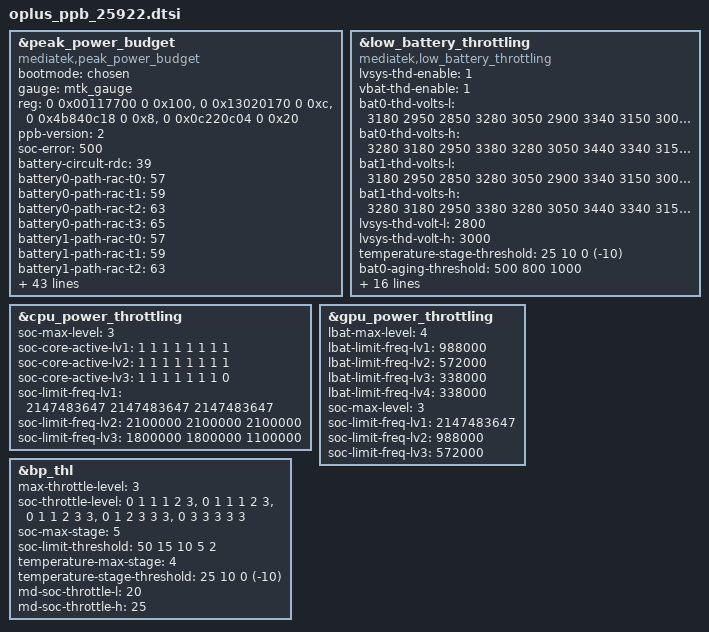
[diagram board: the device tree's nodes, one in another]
// SPDX-License-Identifier: GPL-2.0-only
/*
* Copyright (C) 2021-2020 Oplus. All rights reserved.
*/
#include <dt-bindings/iio/mt635x-auxadc.h>
#include <dt-bindings/pinctrl/mt6991-pinfunc.h>
#include <dt-bindings/pinctrl/mt65xx.h>

&peak_power_budget {
	compatible = "mediatek,peak_power_budget";
	bootmode = <&chosen>;
	gauge = <&mtk_gauge>;
	reg = <0 0x00117700 0 0x100>,
		<0 0x13020170 0 0xc>,
		<0 0x4b840c18 0 0x8>,
		<0 0x0c220c04 0 0x20>;
	reg-names = "ppb_sram",
		"hpt_ctrl","gpu_dbg", "cpu_dbg";

	ppb-version = <2>;
	soc-error = <500>;
	battery-circult-rdc  = <39>;
	battery0-path-rac-t0 = <57>;
	battery0-path-rac-t1 = <59>;
	battery0-path-rac-t2 = <63>;
	battery0-path-rac-t3 = <65>;
	battery1-path-rac-t0 = <57>;
	battery1-path-rac-t1 = <59>;
	battery1-path-rac-t2 = <63>;
	battery1-path-rac-t3 = <65>;
	battery2-path-rac-t0 = <57>;
	battery2-path-rac-t1 = <59>;
	battery2-path-rac-t2 = <63>;
	battery2-path-rac-t3 = <65>;
	temperature-threshold = <25 10 0>;
	system-ocp = <15000>;
	system-uvlo = <2400>;

	soc-max-level = <3>;     //+lv3
	soc-hpt-ctrl-lv1 = <7>;  //lv1 pre-uv on
	soc-hpt-ctrl-lv2 = <7>;  //lv2 pre-uv on  //modify for tablet projects configured graphite battery 
	soc-hpt-ctrl-lv3 = <0>;  //lv3 pre-uv off

	bat-ocv-table-num = <6>;
	bat0-ocv-table-t0-temperature = <50>;
		bat0-ocv-table-t0-qmax = <5443>;
	bat0-ocv-table-t0-size = <100>;
	bat0-ocv-table-t0 = <
			0		44549	0 		342
			550		44408	101 	341
			1100	44302	202 	353
			1649	44213	303 	358
			2199	44122	404 	357
			2749	44031	505 	342
			3299	43945	606 	358
			3848	43852	707 	363
			4398	43757	808 	357
			4948	43662	909 	371
			5498	43560	1010 	361
			6047	43461	1111 	369
			6597	43357	1212 	364
			7147	43253	1313 	372
			7697	43147	1414 	369
			8246	43035	1515 	365
			8796	42927	1616 	388
			9346	42804	1717 	372
			9896	42688	1818 	371
			10445	42575	1919 	387
			10995	42456	2020 	394
			11545	42336	2121 	390
			12095	42218	2222 	405
			12644	42098	2323 	411
			13194	41979	2424 	431
			13744	41857	2525 	432
			14294	41739	2626 	456
			14843	41609	2727 	467
			15393	41467	2828 	491
			15943	41259	2929 	429
			16493	41058	3030 	396
			17042	40908	3131 	371
			17592	40777	3232 	371
			18142	40664	3333 	373
			18692	40553	3434 	370
			19241	40445	3535 	371
			19791	40339	3636 	357
			20341	40239	3737 	370
			20891	40139	3838 	372
			21440	40042	3939 	373
			21990	39945	4040 	371
			22540	39848	4141 	362
			23090	39759	4242 	383
			23639	39672	4343 	387
			24189	39584	4444 	395
			24739	39495	4545 	404
			25289	39403	4646 	406
			25838	39300	4747 	410
			26388	39150	4848 	374
			26938	39000	4949 	362
			27488	38872	5051 	373
			28037	38759	5151 	371
			28587	38645	5252 	379
			29137	38538	5354 	387
			29687	38434	5455 	376
			30236	38332	5555 	388
			30786	38219	5656 	388
			31336	38093	5758 	405
			31886	37974	5859 	412
			32435	37867	5959 	434
			32985	37744	6061 	441
			33535	37633	6162 	436
			34085	37552	6263 	419
			34635	37482	6364 	419
			35184	37422	6465 	421
			35734	37348	6566 	426
			36284	37267	6667 	426
			36834	37148	6768 	426
			37383	37028	6869 	426
			37933	36916	6970 	426
			38483	36803	7071 	426
			39033	36680	7172 	426
			39582	36553	7273 	426
			40132	36421	7374 	426
			40682	36280	7475 	426
			41232	36138	7576 	426
			41781	35984	7677 	426
			42331	35826	7778 	426
			42881	35664	7879 	426
			43431	35502	7980 	426
			43980	35352	8081 	426
			44530	35199	8182 	426
			45080	35046	8283 	426
			45630	34899	8384 	426
			46179	34745	8485 	426
			46729	34582	8586 	426
			47279	34411	8687 	426
			47829	34238	8788 	426
			48378	34048	8889 	426
			48928	33830	8990 	426
			49478	33610	9091 	426
			50028	33380	9192 	426
			50577	33144	9293 	426
			51127	32918	9394 	426
			51677	32691	9495 	426
			52227	32473	9596 	426
			52776	32254	9697 	426
			53326	32015	9798 	426
			53876	31732	9899 	426
			54426	31374	10000 	426
		>;         //modify for tablet projects configured graphite battery 

		bat0-ocv-table-t1-temperature = <25>;
		bat0-ocv-table-t1-qmax = <5443>;
		bat0-ocv-table-t1-size = <100>;
		bat0-ocv-table-t1 = <
			0		44549	0 		342
			550		44408	101 	341
			1100	44302	202 	353
			1649	44213	303 	358
			2199	44122	404 	357
			2749	44031	505 	342
			3299	43945	606 	358
			3848	43852	707 	363
			4398	43757	808 	357
			4948	43662	909 	371
			5498	43560	1010 	361
			6047	43461	1111 	369
			6597	43357	1212 	364
			7147	43253	1313 	372
			7697	43147	1414 	369
			8246	43035	1515 	365
			8796	42927	1616 	388
			9346	42804	1717 	372
			9896	42688	1818 	371
			10445	42575	1919 	387
			10995	42456	2020 	394
			11545	42336	2121 	390
			12095	42218	2222 	405
			12644	42098	2323 	411
			13194	41979	2424 	431
			13744	41857	2525 	432
			14294	41739	2626 	456
			14843	41609	2727 	467
			15393	41467	2828 	491
			15943	41259	2929 	429
			16493	41058	3030 	396
			17042	40908	3131 	371
			17592	40777	3232 	371
			18142	40664	3333 	373
			18692	40553	3434 	370
			19241	40445	3535 	371
			19791	40339	3636 	357
			20341	40239	3737 	370
			20891	40139	3838 	372
			21440	40042	3939 	373
			21990	39945	4040 	371
			22540	39848	4141 	362
			23090	39759	4242 	383
			23639	39672	4343 	387
			24189	39584	4444 	395
			24739	39495	4545 	404
			25289	39403	4646 	406
			25838	39300	4747 	410
			26388	39150	4848 	374
			26938	39000	4949 	362
			27488	38872	5051 	373
			28037	38759	5151 	371
			28587	38645	5252 	379
			29137	38538	5354 	387
			29687	38434	5455 	376
			30236	38332	5555 	388
			30786	38219	5656 	388
			31336	38093	5758 	405
			31886	37974	5859 	412
			32435	37867	5959 	434
			32985	37744	6061 	441
			33535	37633	6162 	436
			34085	37552	6263 	419
			34635	37482	6364 	419
			35184	37422	6465 	421
			35734	37348	6566 	426
			36284	37267	6667 	426
			36834	37148	6768 	426
			37383	37028	6869 	426
			37933	36916	6970 	426
			38483	36803	7071 	426
			39033	36680	7172 	426
			39582	36553	7273 	426
			40132	36421	7374 	426
			40682	36280	7475 	426
			41232	36138	7576 	426
			41781	35984	7677 	426
			42331	35826	7778 	426
			42881	35664	7879 	426
			43431	35502	7980 	426
			43980	35352	8081 	426
			44530	35199	8182 	426
			45080	35046	8283 	426
			45630	34899	8384 	426
			46179	34745	8485 	426
			46729	34582	8586 	426
			47279	34411	8687 	426
			47829	34238	8788 	426
			48378	34048	8889 	426
			48928	33830	8990 	426
			49478	33610	9091 	426
			50028	33380	9192 	426
			50577	33144	9293 	426
			51127	32918	9394 	426
			51677	32691	9495 	426
			52227	32473	9596 	426
			52776	32254	9697 	426
			53326	32015	9798 	426
			53876	31732	9899 	426
			54426	31374	10000 	426
		>;         //modify for tablet projects configured graphite battery 
		
		
		bat0-ocv-table-t2-temperature = <10>;
		bat0-ocv-table-t2-qmax = <5443>;
		bat0-ocv-table-t2-size = <100>;
		bat0-ocv-table-t2 = <
			0		44549	0 		342
			550		44408	101 	341
			1100	44302	202 	353
			1649	44213	303 	358
			2199	44122	404 	357
			2749	44031	505 	342
			3299	43945	606 	358
			3848	43852	707 	363
			4398	43757	808 	357
			4948	43662	909 	371
			5498	43560	1010 	361
			6047	43461	1111 	369
			6597	43357	1212 	364
			7147	43253	1313 	372
			7697	43147	1414 	369
			8246	43035	1515 	365
			8796	42927	1616 	388
			9346	42804	1717 	372
			9896	42688	1818 	371
			10445	42575	1919 	387
			10995	42456	2020 	394
			11545	42336	2121 	390
			12095	42218	2222 	405
			12644	42098	2323 	411
			13194	41979	2424 	431
			13744	41857	2525 	432
			14294	41739	2626 	456
			14843	41609	2727 	467
			15393	41467	2828 	491
			15943	41259	2929 	429
			16493	41058	3030 	396
			17042	40908	3131 	371
			17592	40777	3232 	371
			18142	40664	3333 	373
			18692	40553	3434 	370
			19241	40445	3535 	371
			19791	40339	3636 	357
			20341	40239	3737 	370
			20891	40139	3838 	372
			21440	40042	3939 	373
			21990	39945	4040 	371
			22540	39848	4141 	362
			23090	39759	4242 	383
			23639	39672	4343 	387
			24189	39584	4444 	395
			24739	39495	4545 	404
			25289	39403	4646 	406
			25838	39300	4747 	410
			26388	39150	4848 	374
			26938	39000	4949 	362
			27488	38872	5051 	373
			28037	38759	5151 	371
			28587	38645	5252 	379
			29137	38538	5354 	387
			29687	38434	5455 	376
			30236	38332	5555 	388
			30786	38219	5656 	388
			31336	38093	5758 	405
			31886	37974	5859 	412
			32435	37867	5959 	434
			32985	37744	6061 	441
			33535	37633	6162 	436
			34085	37552	6263 	419
			34635	37482	6364 	419
			35184	37422	6465 	421
			35734	37348	6566 	426
			36284	37267	6667 	426
			36834	37148	6768 	426
			37383	37028	6869 	426
			37933	36916	6970 	426
			38483	36803	7071 	426
			39033	36680	7172 	426
			39582	36553	7273 	426
			40132	36421	7374 	426
			40682	36280	7475 	426
			41232	36138	7576 	426
			41781	35984	7677 	426
			42331	35826	7778 	426
			42881	35664	7879 	426
			43431	35502	7980 	426
			43980	35352	8081 	426
			44530	35199	8182 	426
			45080	35046	8283 	426
			45630	34899	8384 	426
			46179	34745	8485 	426
			46729	34582	8586 	426
			47279	34411	8687 	426
			47829	34238	8788 	426
			48378	34048	8889 	426
			48928	33830	8990 	426
			49478	33610	9091 	426
			50028	33380	9192 	426
			50577	33144	9293 	426
			51127	32918	9394 	426
			51677	32691	9495 	426
			52227	32473	9596 	426
			52776	32254	9697 	426
			53326	32015	9798 	426
			53876	31732	9899 	426
			54426	31374	10000 	426
		>;         //modify for tablet projects configured graphite battery 
		
		bat0-ocv-table-t3-temperature = <0>;
		bat0-ocv-table-t3-qmax = <5028>;
		bat0-ocv-table-t3-size = <100>;
		bat0-ocv-table-t3 = <
			0		44847	0 		2400
			508		44613	101 	2656
			1016	44464	202 	2649
			1524	44358	303 	2622
			2031	44264	404 	2631
			2539	44177	505 	2606
			3047	44095	606 	2594
			3555	44010	707 	2572
			4063	43930	808 	2558
			4571	43843	909 	2558
			5078	43756	1010 	2544
			5586	43663	1111 	2539
			6094	43574	1212 	2519
			6602	43480	1313 	2525
			7110	43380	1414 	2514
			7618	43289	1515 	2521
			8126	43181	1616 	2501
			8633	43078	1717 	2496
			9141	42970	1818 	2485
			9649	42865	1919 	2496
			10157	42752	2020 	2483
			10665	42641	2121 	2481
			11173	42523	2222 	2482
			11680	42416	2323 	2482
			12188	42301	2424 	2496
			12696	42186	2525 	2493
			13204	42068	2626 	2463
			13712	41953	2727 	2433
			14220	41830	2828 	2403
			14728	41712	2929 	2373
			15235	41586	3030 	2343
			15743	41452	3131 	2313
			16251	41304	3232 	2283
			16759	41146	3333 	2200
			17267	40973	3434 	2120
			17775	40806	3535 	2040
			18282	40658	3636 	1960
			18790	40530	3737 	1880
			19298	40416	3838 	1800
			19806	40309	3939 	1800
			20314	40204	4040 	1800
			20822	40103	4141 	1800
			21330	40008	4242 	1800
			21837	39913	4343 	1800
			22345	39825	4444 	1800
			22853	39733	4545 	1800
			23361	39648	4646 	1800
			23869	39563	4747 	1800
			24377	39484	4849 	1800
			24885	39406	4950 	1800
			25392	39327	5050 	1800
			25900	39248	5151 	1800
			26408	39170	5253 	1800
			26916	39099	5354 	1800
			27424	39023	5455 	1800
			27932	38950	5556 	1800
			28439	38865	5656 	1800
			28947	38780	5758 	1800
			29455	38691	5859 	1800
			29963	38584	5960 	1800
			30471	38485	6061 	1800
			30979	38382	6162 	1800
			31487	38282	6263 	1800
			31994	38171	6364 	1800
			32502	38053	6465 	1800
			33010	37939	6566 	1800
			33518	37822	6667 	1600
			34026	37708	6768 	1600
			34534	37589	6869 	1600
			35041	37503	6970 	1580
			35549	37439	7071 	1560
			36057	37372	7172 	1540
			36565	37317	7273 	1520
			37073	37245	7374 	1500
			37581	37140	7475 	1480
			38089	36969	7576 	1460
			38596	36822	7677 	1440
			39104	36693	7778 	1420
			39612	36573	7879 	1400
			40120	36447	7980 	1400
			40628	36326	8081 	1400
			41136	36187	8182 	1400
			41643	36054	8283 	1400
			42151	35912	8384 	1400
			42659	35756	8485 	1400
			43167	35599	8586 	1400
			43675	35438	8687 	1400
			44183	35277	8788 	1400
			44691	35119	8889 	1350
			45198	34959	8990 	1300
			45706	34797	9091 	1250
			46214	34634	9192 	1200
			46722	34462	9293 	1200
			47230	34286	9394 	1100
			47738	34104	9495 	1100
			48245	33906	9596 	1100
			48753	33693	9697 	1000
			49261	33472	9798 	800
			49769	33239	9899 	800
			50277	33004	10000 	700
		>;

		bat0-ocv-table-t4-temperature = <(-10)>;
		bat0-ocv-table-t4-qmax = <4804>;
		bat0-ocv-table-t4-size = <100>;
		bat0-ocv-table-t4 = <
			0		44847	0 		3500
			485		44601	101 	3500
			970		44452	202 	3500
			1456	44343	303 	3500
			1941	44240	404 	3500
			2426	44142	505 	3500
			2911	44058	606 	3500
			3396	43971	707 	3500
			3882	43888	808 	3500
			4367	43805	909 	3500
			4852	43717	1010 	3500
			5337	43633	1111 	3500
			5822	43548	1212 	3500
			6308	43453	1313 	3500
			6793	43362	1414 	3500
			7278	43265	1515 	3500
			7763	43172	1616 	3500
			8248	43078	1717 	3500
			8734	42978	1818 	3500
			9219	42879	1919 	3500
			9704	42774	2020 	3500
			10189	42671	2121 	3500
			10674	42561	2222 	3500
			11160	42452	2323 	3500
			11645	42341	2424 	3500
			12130	42238	2525 	3500
			12615	42117	2626 	3500
			13100	42006	2727 	3500
			13586	41889	2828 	3500
			14071	41764	2929 	3500
			14556	41647	3030 	3500
			15041	41522	3131 	3500
			15526	41417	3232 	3500
			16012	41269	3333 	3500
			16497	41120	3434 	3500
			16982	40975	3535 	3500
			17467	40833	3636 	3500
			17952	40697	3737 	3500
			18437	40575	3838 	3500
			18923	40452	3939 	3500
			19408	40347	4040 	3500
			19893	40246	4141 	3500
			20378	40143	4242 	3500
			20863	40050	4343 	3500
			21349	39957	4444 	3400
			21834	39868	4545 	3350
			22319	39780	4646 	3300
			22804	39690	4747 	3250
			23289	39613	4848 	3200
			23775	39528	4950 	3150
			24260	39449	5050 	3100
			24745	39376	5151 	3050
			25230	39296	5252 	3000
			25715	39227	5353 	3000
			26201	39152	5455 	3000
			26686	39081	5556 	3000
			27171	39008	5657 	3000
			27656	38939	5757 	3000
			28141	38868	5858 	3000
			28627	38791	5960 	3000
			29112	38715	6061 	3000
			29597	38638	6162 	3000
			30082	38550	6263 	3000
			30567	38465	6363 	3000
			31053	38375	6465 	3000
			31538	38279	6566 	2900
			32023	38182	6667 	2800
			32508	38071	6768 	2700
			32993	37965	6869 	2600
			33479	37856	6970 	2500
			33964	37748	7071 	2500
			34449	37631	7172 	2500
			34934	37529	7273 	2500
			35419	37448	7374 	2500
			35905	37384	7475 	2500
			36390	37324	7576 	2500
			36875	37270	7677 	2500
			37360	37208	7778 	2500
			37845	37117	7879 	2500
			38331	36949	7980 	2500
			38816	36766	8081 	2500
			39301	36637	8182 	2500
			39786	36512	8283 	2500
			40271	36387	8384 	2500
			40757	36270	8485 	2500
			41242	36144	8586 	2500
			41727	36016	8687 	2500
			42212	35883	8788 	2500
			42697	35736	8889 	2500
			43183	35586	8990 	2500
			43668	35423	9091 	2500
			44153	35261	9192 	2500
			44638	35088	9293 	2500
			45123	34920	9394 	2500
			45609	34748	9495 	2500
			46094	34570	9596 	2500
			46579	34395	9697 	2500
			47064	34211	9798 	2500
			47549	34023	9899 	2500
			48035	33829	10000 	2500
		>;

		bat0-ocv-table-t5-temperature = <(-20)>;
		bat0-ocv-table-t5-qmax = <4180>;
		bat0-ocv-table-t5-size = <100>;
		bat0-ocv-table-t5 = <
			0		44624	0 		3450
			422		44416	101 	3450
			844		44269	202 	3450
			1267	44151	303 	3450
			1689	44036	404 	3450
			2111	43930	505 	3450
			2533	43829	606 	3475
			2955	43735	707 	3500
			3377	43642	808 	3525
			3800	43550	909 	3550
			4222	43455	1010 	3575
			4644	43367	1111 	3600
			5066	43277	1212 	3625
			5488	43190	1313 	3650
			5911	43099	1414 	3700
			6333	43012	1515 	3730
			6755	42915	1616 	3760
			7177	42823	1717 	3790
			7599	42731	1818 	3820
			8021	42639	1919 	3850
			8444	42545	2020 	3880
			8866	42447	2121 	3910
			9288	42350	2222 	3940
			9710	42255	2323 	3970
			10132	42157	2424 	4000
			10554	42055	2525 	4100
			10977	41954	2626 	4200
			11399	41855	2727 	4300
			11821	41748	2828 	4400
			12243	41636	2929 	4500
			12665	41529	3030 	4600
			13088	41424	3131 	4700
			13510	41314	3232 	4800
			13932	41195	3333 	5000
			14354	41084	3434 	4900
			14776	40972	3535 	4800
			15198	40862	3636 	4700
			15621	40762	3737 	4600
			16043	40659	3838 	4500
			16465	40559	3939 	4500
			16887	40458	4040 	4500
			17309	40356	4141 	4500
			17732	40261	4243 	4500
			18154	40165	4343 	4500
			18576	40075	4444 	4450
			18998	39985	4545 	4400
			19420	39897	4646 	4350
			19842	39817	4747 	4300
			20265	39739	4849 	4250
			20687	39659	4950 	4200
			21109	39575	5050 	4150
			21531	39503	5151 	4100
			21953	39436	5252 	4050
			22376	39364	5354 	4000
			22798	39292	5455 	3950
			23220	39221	5556 	4000
			23642	39153	5657 	4000
			24064	39084	5757 	4000
			24486	39018	5858 	4000
			24909	38956	5960 	4000
			25331	38889	6061 	4000
			25753	38821	6162 	4000
			26175	38755	6263 	4000
			26597	38689	6364 	4000
			27019	38629	6464 	4000
			27442	38552	6566 	4000
			27864	38485	6667 	4000
			28286	38419	6768 	4000
			28708	38347	6869 	4000
			29130	38275	6970 	4000
			29553	38202	7071 	4000
			29975	38130	7172 	4000
			30397	38055	7273 	4000
			30819	37977	7374 	4000
			31241	37897	7475 	4000
			31663	37818	7576 	4200
			32086	37736	7677 	4400
			32508	37650	7778 	4500
			32930	37574	7879 	4600
			33352	37501	7980 	4850
			33774	37434	8081 	5100
			34197	37374	8182 	5350
			34619	37321	8283 	5600
			35041	37275	8384 	5850
			35463	37227	8485 	6100
			35885	37162	8586 	6350
			36307	37088	8687 	6600
			36730	36974	8788 	6850
			37152	36829	8889 	7100
			37574	36674	8990 	7000
			37996	36529	9091 	7000
			38418	36397	9192 	7000
			38841	36275	9293 	7000
			39263	36157	9394 	7000
			39685	36039	9495 	7000
			40107	35916	9596 	7000
			40529	35785	9697 	7000
			40951	35649	9798 	7400
			41374	35511	9899 	7400
			41796	35367	10000 	7400
			>;
	};

&low_battery_throttling {
		compatible = "mediatek,low_battery_throttling";
		lvsys-thd-enable = <1>;
		vbat-thd-enable = <1>;
		bat0-thd-volts-l = <
			3180 2950 2850    //PT threshhold down
			3280 3050 2900
			3340 3150 3000
			3500 3350 3200
			3700 3560 3350>;
		bat0-thd-volts-h = <
			3280 3180 2950
			3380 3280 3050
			3440 3340 3150
			3600 3500 3350
			3800 3700 3560>;
		bat1-thd-volts-l = <
			3180 2950 2850    //PT threshhold down
			3280 3050 2900
			3340 3150 3000
			3500 3350 3200
			3700 3560 3350>;
		bat1-thd-volts-h = <
			3280 3180 2950
			3380 3280 3050
			3440 3340 3150
			3600 3500 3350
			3800 3700 3560>;
		lvsys-thd-volt-l = <2800>;   //0.1V down
		lvsys-thd-volt-h = <3000>;   //0.1V down

		temperature-stage-threshold = <25 10 0 (-10)>;
		bat0-aging-threshold = <500 800 1000>;
		bat0-aging-volts-t0 =  <50 100 150>;
		bat0-aging-volts-t1 =  <50 100 150>;
		bat0-aging-volts-t2 =  <50 100 150>;
		bat0-aging-volts-t3 =  <50 100 150>;
		bat0-aging-volts-t4 =  <50 100 150>;
		bat1-aging-threshold = <500 800 1000>;
		bat1-aging-volts-t0 =  <0 0>;
		bat1-aging-volts-t1 =  <0 0>;
		bat1-aging-volts-t2 =  <0 0>;
		bat1-aging-volts-t3 =  <0 0>;
		bat1-aging-volts-t4 =  <0 0>;
		pt-shutdown-enable = <0>;
		throttle-level =  <0 1 2 3>,
				  <0 1 2 3>,
				  <0 1 2 3>,
				  <0 2 4 3>,
				  <0 2 4 3>;
		bootmode = <&chosen>;
		gauge = <&mtk_gauge>;
};

	&cpu_power_throttling {
		soc-max-level = <3>;
		soc-core-active-lv1 = < 1 1 1 1 1 1 1 1 >;
		soc-core-active-lv2 = < 1 1 1 1 1 1 1 1 >;
		soc-core-active-lv3 = < 1 1 1 1 1 1 1 0 >;

		soc-limit-freq-lv1 = < 2147483647  2147483647 2147483647 >;
		soc-limit-freq-lv2 = < 2100000 2100000 2100000>;    //modify for tablet projects configured graphite battery 
	    soc-limit-freq-lv3 = < 1800000 1800000 1100000>; 
	};

	&gpu_power_throttling {
	
	    lbat-max-level = <4>;       
		lbat-limit-freq-lv1 = <988000>;  //modify for tablet projects configured graphite battery  -20250805
		lbat-limit-freq-lv2 = <572000>;  //modify for tablet projects configured graphite battery  -20250805
		lbat-limit-freq-lv3 = <338000>;
		lbat-limit-freq-lv4 = <338000>; 
		
		soc-max-level = <3>;
		soc-limit-freq-lv1 = <2147483647>;
		soc-limit-freq-lv2 = <988000>;    //modify for tablet projects configured graphite battery 
		soc-limit-freq-lv3 = <572000>;    //modify for tablet projects configured graphite battery  -20250805
	};

	&bp_thl {
		max-throttle-level = <3>;   //+lv3
		soc-throttle-level =
			<0 1 1 1 2 3>, //temperature stage 0
			<0 1 1 1 2 3>, //temperature stage 1
			<0 1 1 2 3 3>, //temperature stage 2
			<0 1 2 3 3 3>,//temperature stage 3
                        <0 3 3 3 3 3>;//temperature stage 4
		soc-max-stage = <5>;
		soc-limit-threshold = <50 15 10 5 2>;

		temperature-max-stage = <4>;
		temperature-stage-threshold = <25 10 0 (-10)>;

		md-soc-throttle-l = <20>;
		md-soc-throttle-h = <25>;
	};
